VERSION ""

NS_ :

BS_:

BU_: Master rtd

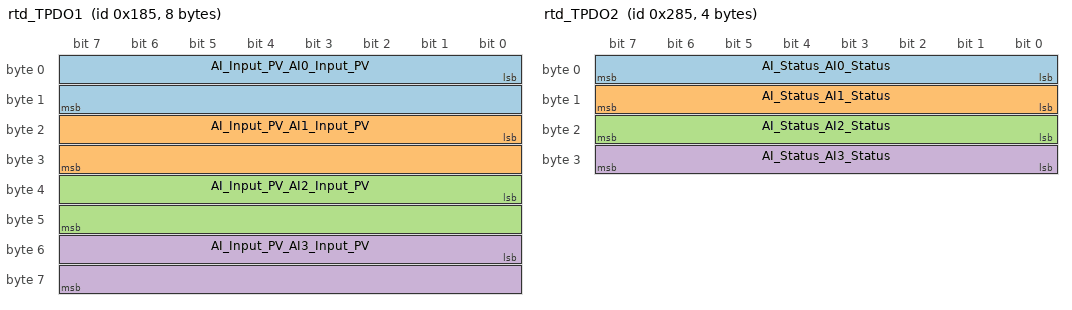
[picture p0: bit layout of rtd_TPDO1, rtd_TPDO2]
BO_ 389 rtd_TPDO1: 8 rtd
 SG_ AI_Input_PV_AI0_Input_PV : 0|16@1- (1,0) [-32768|32767] "" Master
 SG_ AI_Input_PV_AI1_Input_PV : 16|16@1- (1,0) [-32768|32767] "" Master
 SG_ AI_Input_PV_AI2_Input_PV : 32|16@1- (1,0) [-32768|32767] "" Master
 SG_ AI_Input_PV_AI3_Input_PV : 48|16@1- (1,0) [-32768|32767] "" Master

BO_ 645 rtd_TPDO2: 4 rtd
 SG_ AI_Status_AI0_Status : 0|8@1+ (1,0) [0|255] "" Master
 SG_ AI_Status_AI1_Status : 8|8@1+ (1,0) [0|255] "" Master
 SG_ AI_Status_AI2_Status : 16|8@1+ (1,0) [0|255] "" Master
 SG_ AI_Status_AI3_Status : 24|8@1+ (1,0) [0|255] "" Master

BO_ 1797 rtd_Heartbeat: 1 rtd
 SG_ NMT_State : 0|7@1+ (1,0) [0|127] "" Master

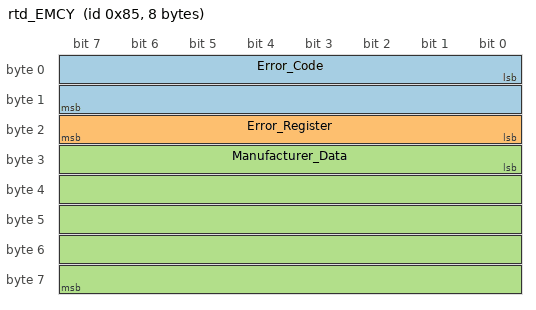
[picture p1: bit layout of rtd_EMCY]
BO_ 133 rtd_EMCY: 8 rtd
 SG_ Error_Code : 0|16@1+ (1,0) [0|65535] "" Master
 SG_ Error_Register : 16|8@1+ (1,0) [0|255] "" Master
 SG_ Manufacturer_Data : 24|40@1+ (1,0) [0|1099511627775] "" Master

BO_ 0 NMT: 2 Master
 SG_ Command : 0|8@1+ (1,0) [0|255] "" rtd
 SG_ Node_ID : 8|8@1+ (1,0) [0|255] "" rtd

BO_ 128 SYNC: 0 Master

CM_ "CANopen network of canopen_config.json, exported by openplc-canopen-deploy TEST";
CM_ BO_ 389 "node 5 TPDO 1, transmission 1";
CM_ SG_ 389 AI_Input_PV_AI0_Input_PV "0x7130:1 INTEGER16 -> %IW100";
CM_ SG_ 389 AI_Input_PV_AI1_Input_PV "0x7130:2 INTEGER16 -> %IW101";
CM_ SG_ 389 AI_Input_PV_AI2_Input_PV "0x7130:3 INTEGER16 -> %IW102";
CM_ SG_ 389 AI_Input_PV_AI3_Input_PV "0x7130:4 INTEGER16 -> %IW103";
CM_ BO_ 645 "node 5 TPDO 2, transmission 1";
CM_ SG_ 645 AI_Status_AI0_Status "0x6150:1 UNSIGNED8 -> %IB100";
CM_ SG_ 645 AI_Status_AI1_Status "0x6150:2 UNSIGNED8 -> %IB101";
CM_ SG_ 645 AI_Status_AI2_Status "0x6150:3 UNSIGNED8 -> %IB102";
CM_ SG_ 645 AI_Status_AI3_Status "0x6150:4 UNSIGNED8 -> %IB103";
CM_ BO_ 1797 "node 5 heartbeat";
CM_ BO_ 133 "node 5 emergency";
CM_ BO_ 0 "NMT node control; Node_ID 0 addresses all nodes";
CM_ BO_ 128 "SYNC";
BA_DEF_ BO_ "GenMsgCycleTime" INT 0 65535;
BA_DEF_DEF_ "GenMsgCycleTime" 0;
BA_ "GenMsgCycleTime" BO_ 389 100;
BA_ "GenMsgCycleTime" BO_ 645 100;
VAL_ 1797 NMT_State 0 "Boot-up" 4 "Stopped" 5 "Operational" 127 "Pre-operational" ;
VAL_ 0 Command 1 "Start" 2 "Stop" 128 "Enter pre-operational" 129 "Reset node" 130 "Reset communication" ;
